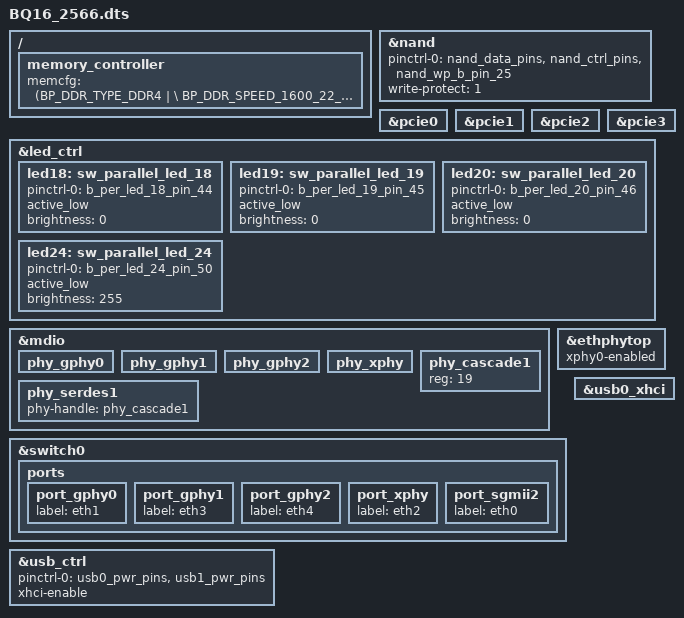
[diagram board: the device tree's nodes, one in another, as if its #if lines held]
#include "6813.dtsi"

/ {
	memory_controller {
		memcfg = <(BP_DDR_TYPE_DDR4       | \
			BP_DDR_SPEED_1600_22_22_22    | \
			BP_DDR_TOTAL_SIZE_1024MB      | \
			BP_DDR_DEVICE_WIDTH_16        | \
			BP_DDR_TOTAL_WIDTH_16BIT      | \
			BP_DDR_TEMP_EXTENDED_ASR      | \
			BP_DDR_SSC_CONFIG_1)>;
	};

};

&nand {
	pinctrl-0 = <&nand_data_pins &nand_ctrl_pins &nand_wp_b_pin_25>;
	write-protect = <1>;
	status = "okay";
};

#if defined(CONFIG_BCM_PCIE_HCD) || defined(CONFIG_BCM_PCIE_HCD_MODULE)
#if defined(CONFIG_REGULATOR) && defined(CONFIG_REGULATOR_FIXED_VOLTAGE)
/**********************************************************************/
/* GPIO: Add one define per GPIO (individual or shared) regulator     */
/*       - Skip if no GPIO regulators in use                          */
/**********************************************************************/
#define PCIE0_REG_GPIO    19    /* SLEEP_0 for vreg_pcie0 node */
#define PCIE1_REG_GPIO    75    /* SLEEP_1 for vreg_pcie1 node */
#define PCIE2_REG_GPIO    78    /* SLEEP_2 for vreg_pcie2 node */
#define PCIE3_REG_GPIO    76    /* SLEEP_3 for vreg_pcie2 node */

#include "../bcm_wlan_regulator.dtsi"
&pcie0 {
	status = "okay";
};
&pcie1 {
	status = "okay";
};
&pcie2 {
	status = "okay";
};
&pcie3 {
	status = "okay";
};
#endif //defined(CONFIG_REGULATOR) && defined(CONFIG_REGULATOR_FIXED_VOLTAGE)
#endif //#if defined(CONFIG_BCM_PCIE_HCD) || defined(CONFIG_BCM_PCIE_HCD_MODULE)

&led_ctrl {
    status="okay";

	/* CLED */
    /* WAN_LED_R */
    led18: sw_parallel_led_18 {
		pinctrl-0 = <&b_per_led_18_pin_44>;
        active_low;
        status="okay";
        brightness = <0>;
	};
    /* WAN_LED_G */
    led19: sw_parallel_led_19 {
		pinctrl-0 = <&b_per_led_19_pin_45>;
        active_low;
        status="okay";
        brightness = <0>;
	};
    /* WAN_LED_B */
    led20: sw_parallel_led_20 {
		pinctrl-0 = <&b_per_led_20_pin_46>;
        active_low;
        status="okay";
        brightness = <0>;
	};
    /* POWER_LED */
    led24: sw_parallel_led_24 {
		pinctrl-0 = <&b_per_led_24_pin_50>;
        active_low;
        status="okay";
        brightness = <255>;
	};

};

/* For AURA72UB0, NP for now
&i2c1 {
	pinctrl-names = "default";
	pinctrl-0 = <&i2c1_sclk_pin_14 &i2c1_sdata_pin_15>;
	status = "okay";
};
*/

&mdio {
    /* Port PHY mapping:
        port_gphy0 <----> phy_gphy0
        port_gphy1 <----> phy_gphy1
        port_gphy2 <----> phy_gphy2
        port_gphy3 <----> phy_gphy3
        port_xphy <-----> phy_xphy      - Internal 10G PHY
        port_sgmii1 <---> phy_serdes0   - BCM84891L
        port_sgmii2 <---> phy_serdes1   - BCM84891L
     */
	phy_gphy0 {
		status = "okay";
	};

	phy_gphy1 {
		status = "okay";
	};

	phy_gphy2 {
		status = "okay";
	};

	/*
	phy_gphy3 {
		status = "okay";
	};
	*/

	phy_xphy {
		status = "okay";
	};

    /* Disable SGMII-1/BCM84891L, not installed
    phy_cascade0 {
        reg = <21>;
		status = "okay";
	};

	phy_serdes0 {
		phy-handle = <&phy_cascade0>;
		status = "okay";
	};
	*/

    /* SGMII-2/BCM84891L */
    phy_cascade1 {
        reg = <19>;
		status = "okay";
	};

	phy_serdes1 {
		phy-handle = <&phy_cascade1>;
		status = "okay";
	};
};

&ethphytop {
    xphy0-enabled;
    status = "okay";
};

&switch0 {
	ports {
		port_gphy0 {
			status = "okay";
			label = "eth1";
		};

		port_gphy1 {
			status = "okay";
			label = "eth3";
		};

		port_gphy2 {
			status = "okay";
			label = "eth4";
		};

/*
		port_gphy3 {
			status = "okay";
		};
*/

		port_xphy {
			status = "okay";
			label = "eth2";
		};

        /* Disable SGMII-1/BCM84891L, not installed
		port_sgmii1 {
			status = "okay";
			label = "eth0";
		};
		/*

        /* SGMII-2/BCM84891L */
		port_sgmii2 {
			status = "okay";
			label = "eth0";
		};
	};
};

&usb_ctrl {
	pinctrl-names = "default";
	pinctrl-0 = <&usb0_pwr_pins &usb1_pwr_pins>;
	status = "okay";
	xhci-enable;
};
&usb0_xhci {
	status = "okay";
};
